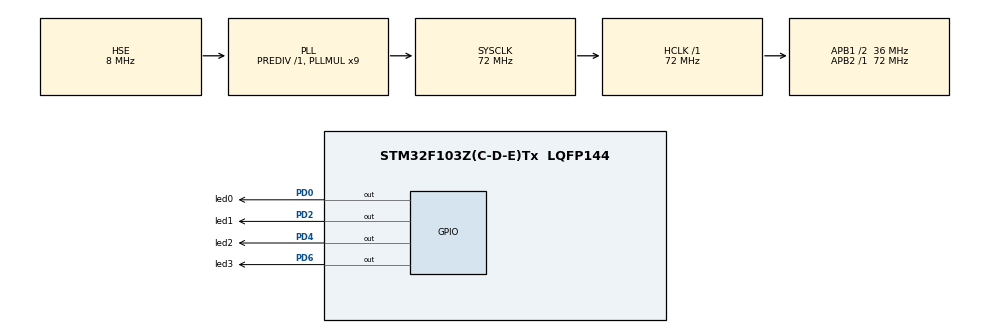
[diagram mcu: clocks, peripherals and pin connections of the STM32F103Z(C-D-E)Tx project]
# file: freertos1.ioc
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Mcu.Family=STM32F1
Mcu.Name=STM32F103Z(C-D-E)Tx
Mcu.Package=LQFP144
NVIC.PriorityGroup=NVIC_PRIORITYGROUP_4
OSC_IN.Mode=HSE-External-Oscillator
OSC_IN.Signal=RCC_OSC_IN
OSC_OUT.Mode=HSE-External-Oscillator
OSC_OUT.Signal=RCC_OSC_OUT
PA13.Mode=Trace_Asynchronous_SW
PA13.Signal=SYS_JTMS-SWDIO
PA14.Mode=Trace_Asynchronous_SW
PA14.Signal=SYS_JTCK-SWCLK
PB3.Mode=Trace_Asynchronous_SW
PB3.Signal=SYS_JTDO-TRACESWO
PD0.GPIO_Label=led0
PD0.GPIO_Speed=GPIO_SPEED_FREQ_HIGH
PD0.Signal=GPIO_Output
PD2.GPIO_Label=led1
PD2.GPIO_Speed=GPIO_SPEED_FREQ_HIGH
PD2.PinState=GPIO_PIN_RESET
PD2.Signal=GPIO_Output
PD4.GPIO_Label=led2
PD4.GPIO_Speed=GPIO_SPEED_FREQ_HIGH
PD4.Signal=GPIO_Output
PD6.GPIO_Label=led3
PD6.GPIO_Speed=GPIO_SPEED_FREQ_HIGH
PD6.Signal=GPIO_Output
ProjectManager.HeapSize=0x200
ProjectManager.StackSize=0x400
ProjectManager.TargetToolchain=Makefile
RCC.AHBFreq_Value=72000000
RCC.APB1CLKDivider=RCC_HCLK_DIV2
RCC.APB1Freq_Value=36000000
RCC.APB1TimFreq_Value=72000000
RCC.APB2Freq_Value=72000000
RCC.APB2TimFreq_Value=72000000
RCC.HCLKFreq_Value=72000000
RCC.PLLMUL=RCC_PLL_MUL9
RCC.PLLSourceVirtual=RCC_PLLSOURCE_HSE
RCC.SYSCLKFreq_VALUE=72000000
RCC.SYSCLKSource=RCC_SYSCLKSOURCE_PLLCLK
RCC.USBFreq_Value=72000000
board=custom

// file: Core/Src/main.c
/* USER CODE BEGIN Header */
/**
  ******************************************************************************
  * @file           : main.c
  * @brief          : Main program body
  ******************************************************************************
  * @attention
  *
  * Copyright (c) 2023 STMicroelectronics.
  * All rights reserved.
  *
  * This software is licensed under terms that can be found in the LICENSE file
  * in the root directory of this software component.
  * If no LICENSE file comes with this software, it is provided AS-IS.
  *
  ******************************************************************************
  */
/* USER CODE END Header */
#include "main.h"
#include "gpio.h"

/* USER CODE BEGIN Includes */
#include <FreeRTOS.h>
#include "freertos.h"
/* USER CODE END Includes */

void SystemClock_Config(void);

int main(void)
{

  /* MCU Configuration--------------------------------------------------------*/

  /* Reset of all peripherals, Initializes the Flash interface and the Systick. */
  HAL_Init();

  /* Configure the system clock */
  SystemClock_Config();

  /* Initialize all configured peripherals */
  MX_GPIO_Init();
  /* USER CODE BEGIN 2 */
  init_system();
  vTaskStartScheduler();

  /* USER CODE END 2 */

  /* Infinite loop */
  while (1)
  {

  }
}

void SystemClock_Config(void)
{
  RCC_OscInitTypeDef RCC_OscInitStruct = {0};
  RCC_ClkInitTypeDef RCC_ClkInitStruct = {0};

  /** Initializes the RCC Oscillators according to the specified parameters
  * in the RCC_OscInitTypeDef structure.
  */
  RCC_OscInitStruct.OscillatorType = RCC_OSCILLATORTYPE_HSE;
  RCC_OscInitStruct.HSEState = RCC_HSE_ON;
  RCC_OscInitStruct.HSEPredivValue = RCC_HSE_PREDIV_DIV1;
  RCC_OscInitStruct.HSIState = RCC_HSI_ON;
  RCC_OscInitStruct.PLL.PLLState = RCC_PLL_ON;
  RCC_OscInitStruct.PLL.PLLSource = RCC_PLLSOURCE_HSE;
  RCC_OscInitStruct.PLL.PLLMUL = RCC_PLL_MUL9;
  if (HAL_RCC_OscConfig(&RCC_OscInitStruct) != HAL_OK)
  {
    Error_Handler();
  }

  /** Initializes the CPU, AHB and APB buses clocks
  */
  RCC_ClkInitStruct.ClockType = RCC_CLOCKTYPE_HCLK|RCC_CLOCKTYPE_SYSCLK
                              |RCC_CLOCKTYPE_PCLK1|RCC_CLOCKTYPE_PCLK2;
  RCC_ClkInitStruct.SYSCLKSource = RCC_SYSCLKSOURCE_PLLCLK;
  RCC_ClkInitStruct.AHBCLKDivider = RCC_SYSCLK_DIV1;
  RCC_ClkInitStruct.APB1CLKDivider = RCC_HCLK_DIV2;
  RCC_ClkInitStruct.APB2CLKDivider = RCC_HCLK_DIV1;

  if (HAL_RCC_ClockConfig(&RCC_ClkInitStruct, FLASH_LATENCY_2) != HAL_OK)
  {
    Error_Handler();
  }
}

void Error_Handler(void)
{
  __disable_irq();
  while (1)
  {
  }
}

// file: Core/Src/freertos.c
//#include "stm32f1xx_hal_def.h"
//#include "FreeRTOS.h"
#include "main.h"
#include "freertos.h"

/* USER CODE BEGIN PREPOSTSLEEP */
__attribute__((weak)) void PreSleepProcessing(TickType_t ulExpectedIdleTime) {
/* place for user code */
}

__attribute__((weak)) void PostSleepProcessing(TickType_t ulExpectedIdleTime) {
/* place for user code */
}
/* USER CODE END PREPOSTSLEEP */

void vApplicationMallocFailedHook(void) {
}

void vApplicationDaemonTaskStartupHook(void) {
}

void vApplicationIdleHook(void) {
}

void vApplicationTickHook(void) {
}

void vApplicationStackOverflowHook(TaskHandle_t xTask, char* pcTaskName) {
}

void vApplicationGetIdleTaskMemory(StaticTask_t** ppxIdleTaskTCBBuffer,
    StackType_t** ppxIdleTaskStackBuffer, uint32_t* pulIdleTaskStackSize) {
}

void vApplicationGetTimerTaskMemory(StaticTask_t** ppxTimerTaskTCBBuffer,
    StackType_t** ppxTimerTaskStackBuffer, uint32_t* pulTimerTaskStackSize ) {
}

static void thread1(void* parameters) {
  int a = 0;
  for(;;++a) {
    HAL_GPIO_WritePin(led0_GPIO_Port, led0_Pin, 0 == a % 2 ? GPIO_PIN_RESET : GPIO_PIN_SET);
    vTaskDelay(1000);
  }
}

static void thread2(void* parameters) {
  int a = 0;
  for(;;++a) {
    HAL_GPIO_WritePin(led1_GPIO_Port, led1_Pin, 0 == a % 2 ? GPIO_PIN_RESET : GPIO_PIN_SET);
    vTaskDelay(2000);
  }
}

tread_info_t tasks[] = {
  {&thread1, "thread1", 512, 0, 1, 0 },
  {&thread2, "thread2", 512, 0, 1, 0 }
};

BaseType_t init_system() {
  TaskHandle_t h;
  BaseType_t r = pdTRUE;
  for(size_t i = 0; i < sizeof(tasks)/sizeof(tread_info_t); ++i)
    if(pdFALSE == xTaskCreate(tasks[i].function, tasks[i].name, tasks[i].stackd_depth,
        tasks[i].parameters, tasks[i].priority, &h))
      r = pdFALSE;
  return r;
}
